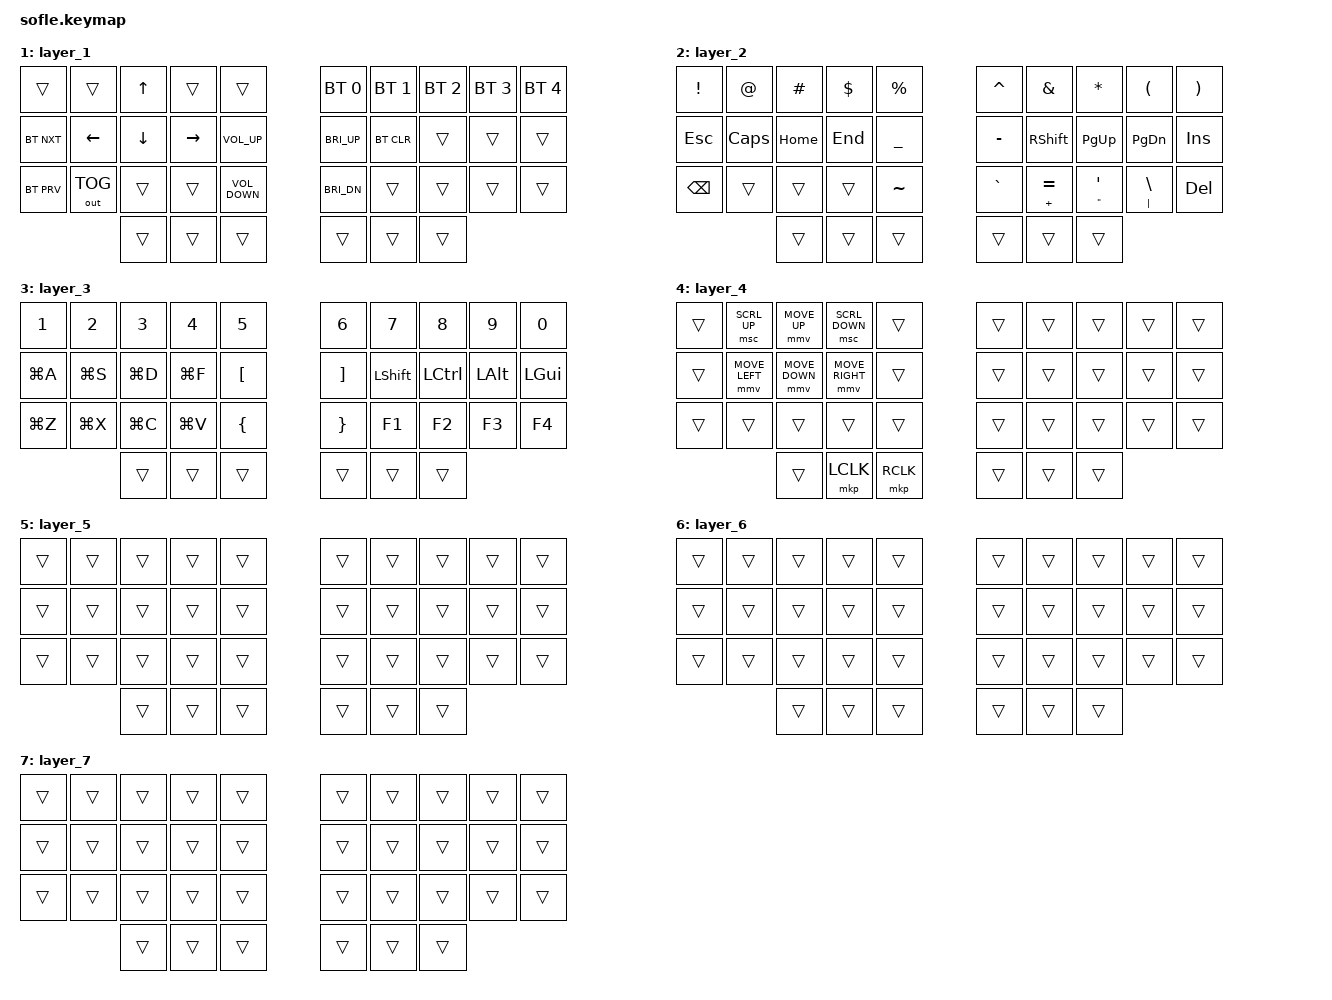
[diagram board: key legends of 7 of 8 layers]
/*
 * Copyright (c) 2020 The ZMK Contributors
 *
 * SPDX-License-Identifier: MIT
 */
#include <dt-bindings/zmk/mouse.h>
#include <behaviors.dtsi>
#include <dt-bindings/zmk/bt.h>
#include <dt-bindings/zmk/keys.h>
#include <dt-bindings/zmk/outputs.h>

#define LOWER 1
#define RAISE 2

&mt {
    tapping-term-ms = <200>;
    flavor = "tap-preferred";
};

&sk {
    release-after-ms = <2000>;
    quick-release;
};

/ {
    combos {
        compatible = "zmk,combos";

        left_bkt {
            bindings = <&kp LBKT>;
            key-positions = <3 2>;
            timeout-ms = <50>;
        };

        right_bkt {
            bindings = <&kp RBKT>;
            key-positions = <6 7>;
            timeout-ms = <50>;
        };

        left_par {
            bindings = <&kp LEFT_PARENTHESIS>;
            key-positions = <12 13>;
            timeout-ms = <50>;
        };

        right_par {
            bindings = <&kp RIGHT_PARENTHESIS>;
            key-positions = <16 17>;
            timeout-ms = <50>;
        };

        left_brace {
            bindings = <&kp LEFT_BRACE>;
            key-positions = <23 22>;
            timeout-ms = <50>;
        };

        right_brace {
            bindings = <&kp RIGHT_BRACE>;
            key-positions = <26 27>;
            timeout-ms = <50>;
        };

        bac {
            bindings = <&kp BACKSLASH>;
            key-positions = <4 5>;
        };

        pipe {
            bindings = <&kp PIPE>;
            key-positions = <14 15>;
        };
    };

    behaviors {
        hm: homerow_mods {
            compatible = "zmk,behavior-hold-tap";
            #binding-cells = <2>;
            tapping-term-ms = <200>;
            flavor = "tap-preferred";
            bindings = <&kp>, <&kp>;
        };

        ltq: ltq {
            compatible = "zmk,behavior-hold-tap";
            #binding-cells = <2>;
            tapping-term-ms = <200>;
            flavor = "hold-preferred";
            bindings = <&mo>, <&kp>;
        };

        as: as {
            compatible = "zmk,behavior-hold-tap";
            bindings = <&kp>, <&kp>;
            #binding-cells = <2>;
            tapping-term-ms = <135>;
            flavor = "tap-preferred";
        };
    };

    keymap {
        compatible = "zmk,keymap";

        layer_0 {
            bindings = <
&kp GRAVE  &kp N1  &kp N2    &kp N3    &kp N4     &kp N5                              &kp N6     &kp N7     &kp N8     &kp N9    &kp N0    &kp DELETE
&kp ESC    &kp Q   &kp W     &kp E     &kp R      &kp T                               &kp Y      &kp U      &kp I      &kp O     &kp P     &kp BSPC
&kp TAB    &kp A   &kp S     &kp D     &kp F      &kp G                               &kp H      &kp J      &kp K      &kp L     &kp SEMI  &kp SQT
&kp LSHFT  &kp Z   &kp X     &kp C     &kp V      &kp B      &kp C_MUTE    &none      &kp N      &kp M      &kp COMMA  &kp DOT   &kp FSLH  &kp RSHFT
                   &kp LGUI  &kp LALT  &kp LCTRL  &mo LOWER  &kp RET       &kp SPACE  &mo RAISE  &kp RCTRL  &kp RALT   &kp RGUI
            >;

            sensor-bindings = <&inc_dec_kp C_VOL_UP C_VOL_DN &inc_dec_kp PG_UP PG_DN>;
        };

        layer_1{
            bindings = <
&trans              &trans                &kp UP            &trans     &trans             &bt BT_SEL 0          &bt BT_SEL 1  &bt BT_SEL 2  &bt BT_SEL 3  &bt BT_SEL 4
&bt BT_NXT          &kp LEFT              &kp DOWN          &kp RIGHT  &kp C_VOLUME_UP    &kp C_BRI_UP          &bt BT_CLR    &trans        &trans        &trans
&bt BT_PRV          &out OUT_TOG          &trans            &trans     &kp C_VOLUME_DOWN  &kp C_BRI_DN          &trans        &trans        &trans        &trans
            &trans                &trans            &trans             &trans             &trans        &trans
            >;
        };

        layer_2 {
            bindings = <
&kp EXCLAMATION          &kp AT_SIGN           &kp HASH          &kp DOLLAR  &kp PERCENT  &kp CARET          &kp AMPERSAND    &kp STAR                        &kp LEFT_PARENTHESIS  &kp RIGHT_PARENTHESIS
&kp ESCAPE               &kp CAPSLOCK          &kp HOME          &kp END     &kp UNDER    &kp MINUS          &kp RIGHT_SHIFT  &kp PAGE_UP                     &kp PAGE_DOWN         &kp INSERT
&kp BACKSPACE            &trans                &trans            &trans      &kp TILDE    &kp GRAVE          &as PLUS EQUAL   &as DOUBLE_QUOTES SINGLE_QUOTE  &as PIPE BACKSLASH    &kp DEL
                 &trans                &trans            &trans              &trans       &trans     &trans
            >;
        };

        layer_3 {
            bindings = <
&kp NUMBER_1          &kp NUMBER_2          &kp NUMBER_3          &kp NUMBER_4  &kp NUMBER_5      &kp NUMBER_6               &kp NUMBER_7    &kp NUMBER_8      &kp NUMBER_9  &kp NUMBER_0
&kp LG(A)             &kp LG(S)             &kp LG(D)             &kp LG(F)     &kp LEFT_BRACKET  &kp RIGHT_BRACKET          &kp LEFT_SHIFT  &kp LEFT_CONTROL  &kp LEFT_ALT  &kp LEFT_GUI
&kp LG(Z)             &kp LG(X)             &kp LG(C)             &kp LG(V)     &kp LEFT_BRACE    &kp RIGHT_BRACE            &kp F1          &kp F2            &kp F3        &kp F4
              &trans                &trans                &trans                &trans            &trans             &trans
            >;
        };

        layer_4 {
            bindings = <
&trans          &msc SCRL_UP   &mmv MOVE_UP  &msc SCRL_DOWN  &trans  &trans          &trans  &trans  &trans  &trans
&trans          &mmv MOVE_LEFT  &mmv MOVE_DOWN  &mmv MOVE_RIGHT  &trans  &trans          &trans  &trans  &trans  &trans
&trans          &trans          &trans          &trans  &trans  &trans          &trans  &trans  &trans  &trans
        &trans          &mkp LCLK  &mkp RCLK         &trans  &trans  &trans
            >;
        };

        layer_5 {
            bindings = <
&trans          &trans          &trans          &trans  &trans  &trans          &trans  &trans  &trans  &trans
&trans          &trans          &trans          &trans  &trans  &trans          &trans  &trans  &trans  &trans
&trans          &trans          &trans          &trans  &trans  &trans          &trans  &trans  &trans  &trans
        &trans          &trans          &trans          &trans  &trans  &trans
            >;
        };

        layer_6 {
            bindings = <
&trans          &trans          &trans          &trans  &trans  &trans          &trans  &trans  &trans  &trans
&trans          &trans          &trans          &trans  &trans  &trans          &trans  &trans  &trans  &trans
&trans          &trans          &trans          &trans  &trans  &trans          &trans  &trans  &trans  &trans
        &trans          &trans          &trans          &trans  &trans  &trans
            >;
        };

        layer_7 {
            bindings = <
&trans          &trans          &trans          &trans  &trans  &trans          &trans  &trans  &trans  &trans
&trans          &trans          &trans          &trans  &trans  &trans          &trans  &trans  &trans  &trans
&trans          &trans          &trans          &trans  &trans  &trans          &trans  &trans  &trans  &trans
        &trans          &trans          &trans          &trans  &trans  &trans
            >;
        };
    };
};
